# soc-dvt-2753c12 register map
Vendor: litex
Registers are 32-bit, read-write, reset 0x0 unless marked. A register's access mark holds for its fields unless they carry their own. Offsets are from the block's base; [hi:lo] are bit positions.

## TRNG_KERNEL
Base 0xF001C000
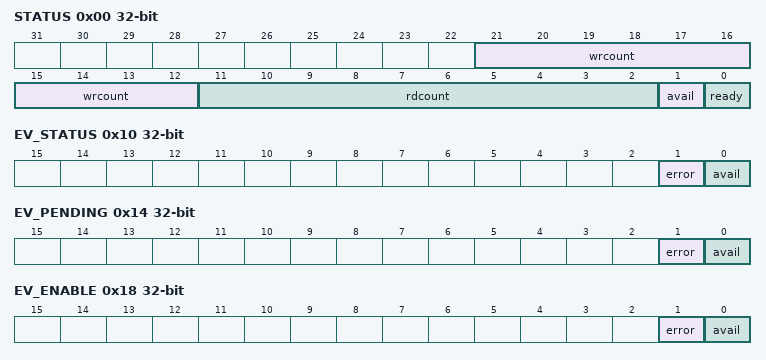
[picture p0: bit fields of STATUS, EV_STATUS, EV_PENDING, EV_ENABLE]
0x00 STATUS
  [21:12] wrcount — Write fifo pointer
  [11:2] rdcount — Read fifo pointer
  [1] avail — Indicates that the read FIFO is not empty
  [0] ready — When set, indicates that the TRNG interface is capable of generating numbers
0x04 DATA
  [31:0] data — (DEPRECATED - use `urandom`) Latest random data from the FIFO; only valid if ``avail`` bit is set. This interface is preserved primarily for test programs to access raw TRNG data, but normal kernel code should never use this port, due to a race condition with the automatic reseeding algorithm for urandom.
0x08 URANDOM — Unlimited random numbers, output from the ChaCha conditioner. Generally, you want to use this.
0x0C URANDOM_VALID — Set when `urandom` is valid. Always check before taking `urandom`
  [0] urandom_valid
0x10 EV_STATUS — Triggered whenever an underrun condition first occurs on the kernel interface
  [1] error — Level of the ``error`` event
  [0] avail — Level of the ``avail`` event
0x14 EV_PENDING — Triggered whenever an underrun condition first occurs on the kernel interface
  [1] error — Triggered whenever an underrun condition first occurs on the kernel interface
  [0] avail — Triggered anytime there is data available on the kernel interface
0x18 EV_ENABLE — Triggered whenever an underrun condition first occurs on the kernel interface
  [1] error — Write a ``1`` to enable the ``error`` Event
  [0] avail — Write a ``1`` to enable the ``avail`` Event

## TRNG
Base 0xF001E000
0x00 XADC_TEMPERATURE — Raw Temperature value from XADC. Temperature (C) = ``Value`` x 503.975 / 4096 - 273.15.
  [11:0] xadc_temperature
0x04 XADC_VCCINT — Raw VCCINT value from XADC. VCCINT (V) = ``Value`` x 3 / 4096.
  [11:0] xadc_vccint
0x08 XADC_VCCAUX — Raw VCCAUX value from XADC. VCCAUX (V) = ``Value`` x 3 / 4096.
  [11:0] xadc_vccaux
0x0C XADC_VCCBRAM — Raw VCCBRAM value from XADC. VCCBRAM (V) = ``Value`` x 3 / 4096.
  [11:0] xadc_vccbram
0x10 XADC_VBUS — Raw VBUS value from XADC
  [11:0] xadc_vbus
0x14 XADC_USB_P — Voltage on USB_P pin
  [11:0] xadc_usb_p
0x18 XADC_USB_N — Voltage on USB_N pin
  [11:0] xadc_usb_n
0x1C XADC_NOISE0 — Raw noise0
  [11:0] xadc_noise0
0x20 XADC_NOISE1 — Raw noise1
  [11:0] xadc_noise1
0x24 XADC_EOC — End of Convertion Status, ``1``: Convertion Done.
  [0] xadc_eoc
0x28 XADC_EOS — End of Sequence Status, ``1``: Sequence Done.
  [0] xadc_eos
0x2C XADC_GPIO5 — GPIO5 value
  [11:0] xadc_gpio5
0x30 XADC_GPIO2 — GPIO2 value
  [11:0] xadc_gpio2
0x34 XADC_DRP_ENABLE
  [0] xadc_drp_enable
0x38 XADC_DRP_READ
  [0] xadc_drp_read
0x3C XADC_DRP_WRITE
  [0] xadc_drp_write
0x40 XADC_DRP_DRDY
  [0] xadc_drp_drdy
0x44 XADC_DRP_ADR
  [6:0] xadc_drp_adr
0x48 XADC_DRP_DAT_W
  [15:0] xadc_drp_dat_w
0x4C XADC_DRP_DAT_R
  [15:0] xadc_drp_dat_r

## SHA512
Base 0xF001F000
0x00 POWER
  [0] on — Writing `1` turns on the clocks to this block, `0` stops the clocks (for power savings)
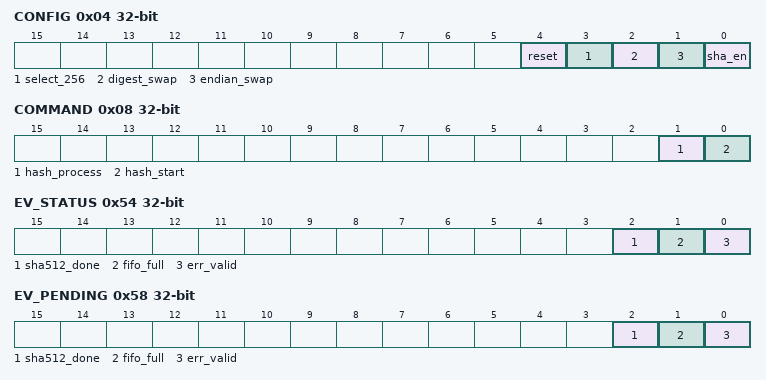
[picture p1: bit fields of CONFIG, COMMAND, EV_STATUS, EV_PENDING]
0x04 CONFIG — Configuration register for the HMAC block
  [4] reset — Resets the hardware. Power must be on for this to take effect.
  [3] select_256 — Select SHA512/256 IV constants when set to `1`
  [2] digest_swap — Swap the endianness on the output digest
  [1] endian_swap — Swap the endianness on the input data
  [0] sha_en — Enable the SHA512 core
0x08 COMMAND — Command register for the HMAC block
  [1] hash_process — Writing a 1 digests the hash data
  [0] hash_start — Writing a 1 indicates the beginning of hash data
0x0C DIGEST01 — Bits 32-63 of `SHA512_DIGEST0`. digest word 0
  [31:0] digest0
0x10 DIGEST00 — Bits 0-31 of `SHA512_DIGEST0`.
  [31:0] digest0
0x14 DIGEST11 — Bits 32-63 of `SHA512_DIGEST1`. digest word 1
  [31:0] digest1
0x18 DIGEST10 — Bits 0-31 of `SHA512_DIGEST1`.
  [31:0] digest1
0x1C DIGEST21 — Bits 32-63 of `SHA512_DIGEST2`. digest word 2
  [31:0] digest2
0x20 DIGEST20 — Bits 0-31 of `SHA512_DIGEST2`.
  [31:0] digest2
0x24 DIGEST31 — Bits 32-63 of `SHA512_DIGEST3`. digest word 3
  [31:0] digest3
0x28 DIGEST30 — Bits 0-31 of `SHA512_DIGEST3`.
  [31:0] digest3
0x2C DIGEST41 — Bits 32-63 of `SHA512_DIGEST4`. digest word 4
  [31:0] digest4
0x30 DIGEST40 — Bits 0-31 of `SHA512_DIGEST4`.
  [31:0] digest4
0x34 DIGEST51 — Bits 32-63 of `SHA512_DIGEST5`. digest word 5
  [31:0] digest5
0x38 DIGEST50 — Bits 0-31 of `SHA512_DIGEST5`.
  [31:0] digest5
0x3C DIGEST61 — Bits 32-63 of `SHA512_DIGEST6`. digest word 6
  [31:0] digest6
0x40 DIGEST60 — Bits 0-31 of `SHA512_DIGEST6`.
  [31:0] digest6
0x44 DIGEST71 — Bits 32-63 of `SHA512_DIGEST7`. digest word 7
  [31:0] digest7
0x48 DIGEST70 — Bits 0-31 of `SHA512_DIGEST7`.
  [31:0] digest7
0x4C MSG_LENGTH1 — Bits 32-63 of `SHA512_MSG_LENGTH`. Bottom 64 bits of length of digested message, in bits
  [31:0] msg_length
0x50 MSG_LENGTH0 — Bits 0-31 of `SHA512_MSG_LENGTH`.
  [31:0] msg_length
0x54 EV_STATUS — SHA512 is done
  [2] sha512_done — Level of the ``sha512_done`` event
  [1] fifo_full — Level of the ``fifo_full`` event
  [0] err_valid — Level of the ``err_valid`` event
0x58 EV_PENDING — SHA512 is done
  [2] sha512_done — SHA512 is done
  [1] fifo_full — FIFO is full
  [0] err_valid — Error flag was generated
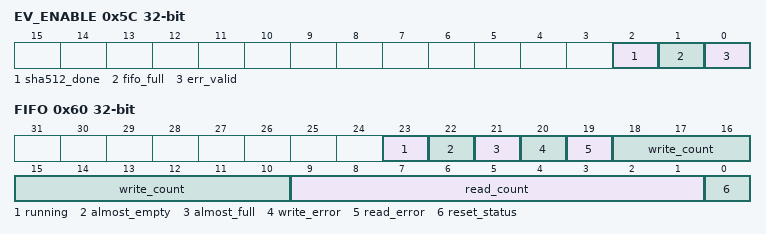
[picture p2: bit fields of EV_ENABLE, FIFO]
0x5C EV_ENABLE — SHA512 is done
  [2] sha512_done — Write a ``1`` to enable the ``sha512_done`` Event
  [1] fifo_full — Write a ``1`` to enable the ``fifo_full`` Event
  [0] err_valid — Write a ``1`` to enable the ``err_valid`` Event
0x60 FIFO — FIFO status
  [23] running — hash engine is running and controls are locked out
  [22] almost_empty
  [21] almost_full
  [20] write_error — write error occurred
  [19] read_error — read error occurred
  [18:10] write_count — write pointer
  [9:1] read_count — read pointer
  [0] reset_status — when set, the block is undergoing a soft reset
